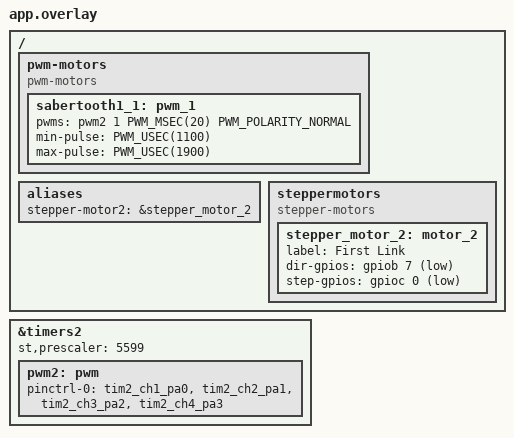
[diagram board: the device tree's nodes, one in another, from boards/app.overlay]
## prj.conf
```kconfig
CONFIG_GPIO=y
CONFIG_SERIAL=y


CONFIG_PWM=y
CONFIG_UART_CONSOLE=y


CONFIG_LOG=y
CONFIG_PRINTK=y
CONFIG_SYSTEM_WORKQUEUE_STACK_SIZE=2048
CONFIG_SYSTEM_WORKQUEUE_PRIORITY=-1
CONFIG_THREAD_NAME=y
```

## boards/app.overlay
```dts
/ {
    pwm-motors {
        compatible = "pwm-motors";
        sabertooth1_1: pwm_1 {
            status = "okay";
            pwms = <&pwm2 1 PWM_MSEC(20) PWM_POLARITY_NORMAL>;
            min-pulse = <PWM_USEC(1100)>;
            max-pulse = <PWM_USEC(1900)>;
        };
    };
};

&timers2 {
    status = "okay";
    st,prescaler = <5599>;
    pwm2: pwm {
        status = "okay";
        pinctrl-0 = <&tim2_ch1_pa0 &tim2_ch2_pa1 &tim2_ch3_pa2 &tim2_ch4_pa3>;
        pinctrl-names = "default";
    };
};

/ {

 aliases {
   stepper-motor2 = &stepper_motor_2;
  };

  steppermotors {
   compatible = "stepper-motors";
   stepper_motor_2: motor_2 {
      label = "First Link";
      dir-gpios = <&gpiob 7 GPIO_ACTIVE_LOW>;
      step-gpios = <&gpioc 0 GPIO_ACTIVE_LOW>;
    };
  };
};
```

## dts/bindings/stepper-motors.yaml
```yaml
description: Stepper motors driven by TB6600 (parent node)

compatible: stepper-motors

child-binding:
  description: GPIO-driven dc motor (child node)
  properties:
    dir-gpios:
      required: true
      type: phandle-array
      description: |
        Dir pin for the motor

    step-gpios:
      required: true
      type: phandle-array
      description: |
        Step pin for the motor

    label:
      type: string
      description: |
        Human readable string describing the motor. 
```

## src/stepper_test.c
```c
#include <zephyr/kernel.h>
#include <zephyr/device.h>
#include <zephyr/devicetree.h>
#include <zephyr/drivers/gpio.h>
#include <zephyr/sys/printk.h>
#include <math.h>
#include <zephyr/logging/log.h>

LOG_MODULE_REGISTER(stepper_test, CONFIG_LOG_DEFAULT_LEVEL);
#define HIGH_PULSE 1
#define LOW_PULSE 0
#define M_PI 3.14159265358979323847

// DT spec for stepper, now for a single motor
const struct stepper_motor {
    const struct gpio_dt_spec dir;
    const struct gpio_dt_spec step;
} stepper = {
    .dir = GPIO_DT_SPEC_GET(DT_ALIAS(stepper_motor2), dir_gpios),
    .step = GPIO_DT_SPEC_GET(DT_ALIAS(stepper_motor2), step_gpios)
};

// ranges used in interpolation;
uint16_t channel_range[] = {0, 950, 2047};
uint16_t *ch;
int pos = 0;

int _Stepper_motor_write(const struct stepper_motor *motor, uint16_t cmd, int current_pos) {
    if (cmd == HIGH_PULSE) {
        gpio_pin_set_dt(&(motor->dir), 1); // clockwise
        current_pos += 1;
    } else if(cmd == LOW_PULSE) {
        gpio_pin_set_dt(&(motor->dir), 0); // anti-clockwise
        current_pos -= 1;
    }
    else return current_pos;
    switch (current_pos & 0x03) {
    case 0:
        gpio_pin_set_dt(&(motor->step), 0);
        break;
    case 1:
        gpio_pin_set_dt(&(motor->step), 1);
        break;
    case 2:
        gpio_pin_set_dt(&(motor->step), 1);
        break;
    case 3:
        gpio_pin_set_dt(&(motor->step), 0);
        break;
    }
    return current_pos;
}

void _arm_joints(struct k_work *work) {
    uint16_t cmd = HIGH_PULSE;
    pos = _Stepper_motor_write(&stepper, cmd, pos);
}
K_WORK_DEFINE(stepper_work, _arm_joints);

/* Timer callback: schedule the work */
void stepper_timer_handler(struct k_timer *timer) {
    k_work_submit(&stepper_work);
}
K_TIMER_DEFINE(my_timer, stepper_timer_handler, NULL);

int main() {
    printk("Stepper Motor Test (Single Motor)\n");

    if (!gpio_is_ready_dt(&stepper.dir)) {
        printk("Stepper Motor: Dir is not ready\n");
        return 0;
    }
    if (!gpio_is_ready_dt(&stepper.step)) {
        printk("Stepper Motor: Step is not ready\n");
        return 0;
    }

    if (gpio_pin_configure_dt(&(stepper.dir), GPIO_OUTPUT_INACTIVE)) {
        printk("Error: Stepper motor dir not configured\n");
        return 0;
    }
    if (gpio_pin_configure_dt(&(stepper.step), GPIO_OUTPUT_INACTIVE)) {
        printk("Error: Stepper motor step not configured\n");
        return 0;
    }

    printk("Initialization completed successfully!\n");
    k_timer_start(&my_timer, K_USEC(120), K_USEC(50));
    
    /* while(true){ */
    /* k_sleep(K_FOREVER); */
    /* } */
}
```
